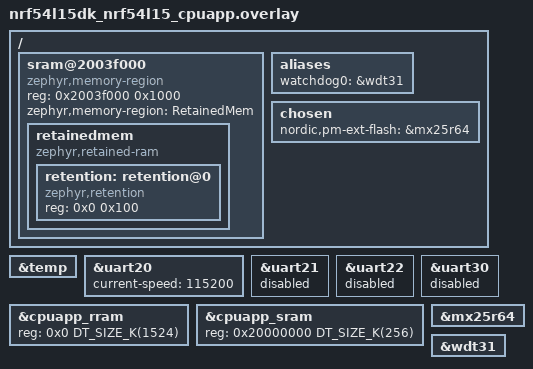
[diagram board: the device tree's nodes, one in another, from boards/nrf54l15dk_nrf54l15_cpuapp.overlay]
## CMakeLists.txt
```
cmake_minimum_required(VERSION 3.20.0)

find_package(Zephyr HINTS $ENV{ZEPHYR_BASE})

project(nrf54_soil)

# Enable GNU STD support for Matter to use
include(${ZEPHYR_CONNECTEDHOMEIP_MODULE_DIR}/config/nrfconnect/app/enable-gnu-std.cmake)

# Matter data model generation
include(${ZEPHYR_CONNECTEDHOMEIP_MODULE_DIR}/src/app/chip_data_model.cmake)

target_include_directories(app PRIVATE
    src
    src/zap-generated
)

target_sources(app PRIVATE
    src/main.cpp
    src/app_task.cpp
    src/retained.cpp
)

target_sources_ifdef(CONFIG_APP_BATTERY_MONITORING app PRIVATE
    src/battery.cpp
)

target_include_directories(matter-data-model PUBLIC
    src
)

chip_configure_data_model(app
    BYPASS_IDL
    GEN_DIR src/zap-generated
    ZAP_FILE ${CMAKE_CURRENT_SOURCE_DIR}/src/sensor.zap
)
```

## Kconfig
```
mainmenu "nRF54 Soil Moisture Sensor Configuration"

config APP_BATTERY_MONITORING
	bool "Enable battery voltage monitoring"
	default y
	select ADC
	help
	  Enable battery voltage monitoring via ADC and voltage divider.

config APP_TEMPERATURE_MONITORING
	bool "Enable temperature monitoring"
	default y
	select SENSOR
	help
	  Enable internal die temperature sensor monitoring.

config APP_MEASUREMENT_INTERVAL_SEC
	int "Measurement interval (seconds)"
	default 300
	help
	  Time between periodic measurements. Device sleeps between readings.


choice OPENTHREAD_DEVICE_TYPE
	default OPENTHREAD_MTD
endchoice

source "${ZEPHYR_CONNECTEDHOMEIP_MODULE_DIR}/config/nrfconnect/chip-module/Kconfig.features"
source "${ZEPHYR_CONNECTEDHOMEIP_MODULE_DIR}/config/nrfconnect/chip-module/Kconfig.defaults"
source "Kconfig.zephyr"
```

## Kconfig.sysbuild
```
# nRF54 Soil Moisture Sensor - Sysbuild Configuration

#### Bootloader
choice BOOTLOADER
	default BOOTLOADER_MCUBOOT
endchoice

if BOOTLOADER_MCUBOOT

config PM_OVERRIDE_EXTERNAL_DRIVER_CHECK
	default y

# MCUboot padding size
config PM_MCUBOOT_PAD
	default 0x800

# Use overwrite-only mode (simpler, no swap)
choice MCUBOOT_MODE
	default MCUBOOT_MODE_OVERWRITE_ONLY
endchoice

endif # BOOTLOADER_MCUBOOT

source "share/sysbuild/Kconfig"
```

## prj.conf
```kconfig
# nRF54 Soil Moisture Sensor - Debug Configuration
# Development build with full logging

# Application features
CONFIG_APP_TEMPERATURE_MONITORING=y
CONFIG_APP_MEASUREMENT_INTERVAL_SEC=5

# Enable CHIP
CONFIG_CHIP=y
CONFIG_CHIP_DEVICE_PRODUCT_ID=32781
CONFIG_CHIP_PROJECT_CONFIG="src/chip_project_config.h"
CONFIG_STD_CPP17=y
CONFIG_THREAD_NAME=y
CONFIG_MPU_STACK_GUARD=y
CONFIG_CHIP_LIB_SHELL=y
CONFIG_CHIP_ENABLE_PAIRING_AUTOSTART=y

# Enable Intermittently Connected Device support,
# with Long Idle Time to reduce power usage
CONFIG_CHIP_ENABLE_ICD_SUPPORT=y
CONFIG_CHIP_ICD_LIT_SUPPORT=y

# Enable Matter extended announcement and increase duration to 1 hour
CONFIG_CHIP_BLE_EXT_ADVERTISING=y
CONFIG_CHIP_BLE_ADVERTISING_DURATION=60

# OpenThread shell for debugging
CONFIG_OPENTHREAD_SHELL=y
CONFIG_SHELL_BACKEND_SERIAL_RX_RING_BUFFER_SIZE=256

# GRTC timer for wakeup from System OFF
CONFIG_NRF_GRTC_TIMER=y

# RAM retention in System OFF
CONFIG_RETAINED_MEM=y
CONFIG_RETAINED_MEM_MUTEX_FORCE_DISABLE=y
CONFIG_RETENTION=y
CONFIG_CRC=y

# Hardware info for reset cause detection
CONFIG_HWINFO=y

# Power Management
CONFIG_PM_DEVICE=y
CONFIG_PM_DEVICE_RUNTIME=y

# System Off (deep sleep)
CONFIG_POWEROFF=y

# Memory footprint
CONFIG_HEAP_MEM_POOL_SIZE=1024
CONFIG_IDLE_STACK_SIZE=256

# Minimal libc
CONFIG_MINIMAL_LIBC=y

# Console for debugging
CONFIG_CONSOLE=y
CONFIG_UART_CONSOLE=y

# Configure UART async logging and shell
CONFIG_LOG=y
CONFIG_LOG_MODE_DEFERRED=y
CONFIG_LOG_PROCESS_THREAD_STACK_SIZE=1024
CONFIG_LOG_BUFFER_SIZE=4096
CONFIG_LOG_FUNC_NAME_PREFIX_DBG=n
CONFIG_SHELL=y
CONFIG_SHELL_LOG_BACKEND=y

# Size optimizations
CONFIG_SIZE_OPTIMIZATIONS=y
CONFIG_LTO=y

# Matter/CHIP size optimizations
CONFIG_CHIP_LOG_SIZE_OPTIMIZATION=y
CONFIG_CHIP_TASK_STACK_SIZE=6144
CONFIG_CHIP_MALLOC_SYS_HEAP_SIZE=8192
CONFIG_CHIP_SYSTEM_PACKETBUFFER_POOL_SIZE=10
CONFIG_CHIP_OTA_REQUESTOR_BUFFER_SIZE=512

# Reduce BLE buffers
CONFIG_BT_BUF_EVT_RX_COUNT=8
CONFIG_BT_BUF_ACL_RX_COUNT=4
CONFIG_BT_BUF_CMD_TX_COUNT=4

# TODO Not sure why this is needed, without it we stack overflow main upon commisioning
CONFIG_MAIN_STACK_SIZE=8196
CONFIG_MATTER_LOG_LEVEL_DBG=y
```

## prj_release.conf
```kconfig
# nRF54 Soil Moisture Sensor - Release Configuration Overrides
# Optimized to reduce power consumption

# Application features
CONFIG_APP_MEASUREMENT_INTERVAL_SEC=300

# Disable all logging
CONFIG_LOG=n

# Disable Matter/CHIP logging (0 = OFF)
CONFIG_CHIP_APP_LOG_LEVEL=0

# Disable console/UART
CONFIG_CONSOLE=n
CONFIG_UART_CONSOLE=n
CONFIG_SERIAL=n

# Disable assertions
CONFIG_ASSERT=n
CONFIG_ASSERT_VERBOSE=n

# Disable debug features
CONFIG_DEBUG=n
CONFIG_DEBUG_INFO=n
CONFIG_THREAD_NAME=n
CONFIG_PRINTK=n
CONFIG_BOOT_BANNER=n

# Disable shell
CONFIG_SHELL=n
CONFIG_CHIP_LIB_SHELL=n
```

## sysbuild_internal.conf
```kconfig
SB_CONFIG_MATTER=y
SB_CONFIG_PM_OVERRIDE_EXTERNAL_DRIVER_CHECK=n
SB_CONFIG_PM_EXTERNAL_FLASH_MCUBOOT_SECONDARY=n

# Enable image compression
SB_CONFIG_MCUBOOT_MODE_OVERWRITE_ONLY=y
SB_CONFIG_MCUBOOT_COMPRESSED_IMAGE_SUPPORT=y
```

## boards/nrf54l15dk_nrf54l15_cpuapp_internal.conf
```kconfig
#
# Copyright (c) 2024 Nordic Semiconductor ASA
#
# SPDX-License-Identifier: LicenseRef-Nordic-5-Clause
#

# Disable SPI
CONFIG_CHIP_SPI_NOR=n

# Enable LTO to decrease the flash usage.
CONFIG_LTO=y
CONFIG_ISR_TABLES_LOCAL_DECLARATION=y
```

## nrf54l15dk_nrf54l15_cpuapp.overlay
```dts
/*
 * Device Tree Overlay for nRF54 Soil Sensor
 * Configures ADC for battery voltage monitoring
 */

#include <zephyr/dt-bindings/adc/nrf-saadc.h>

/ {
	/* Define voltage divider on battery input */
	vbatt {
		compatible = "voltage-divider";
		io-channels = <&adc 0>;
		output-ohms = <22000000>;  /* 22M lower resistor */
		full-ohms = <44000000>;    /* 22M + 22M = 44M total (1:2 divider) */
		/* High resistance (22M) minimizes current drain: 4.2V/44M = 95nA */
	};

	/* Retained RAM for state across System OFF */
	sram@2003f000 {
		compatible = "zephyr,memory-region", "mmio-sram";
		reg = <0x2003f000 0x1000>;
		zephyr,memory-region = "RetainedMem";
		status = "okay";

		retainedmem {
			compatible = "zephyr,retained-ram";
			status = "okay";
			#address-cells = <1>;
			#size-cells = <1>;

			retention: retention@0 {
				compatible = "zephyr,retention";
				status = "okay";
				reg = <0x0 0x100>;
			};
		};
	};

	/* Alias for easy access */
	aliases {
		battery-adc = &adc;
	};
};

/* Configure SAADC for battery voltage measurement */
&adc {
	status = "okay";
	#address-cells = <1>;
	#size-cells = <0>;

	channel@0 {
		reg = <0>;
		zephyr,gain = "ADC_GAIN_1_6";
		zephyr,reference = "ADC_REF_INTERNAL";
		zephyr,acquisition-time = <ADC_ACQ_TIME_DEFAULT>;
		zephyr,input-positive = <NRF_SAADC_AIN0>;  /* P0.00 */
		zephyr,resolution = <12>;
		zephyr,oversampling = <4>;  /* Average 4 samples for stability */
	};
};

/* Enable internal temperature sensor */
&temp {
	status = "okay";
};

/* Keep UART20 for console (it's the default console) */
&uart20 {
	status = "okay";
	current-speed = <115200>;
};

/* Disable unused peripherals to save power */
&uart21 {
	status = "disabled";
};

&uart22 {
	status = "disabled";
};

&uart30 {
	status = "disabled";
};
```

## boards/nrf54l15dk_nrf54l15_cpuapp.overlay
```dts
/ {
	/* Retained RAM for state across System OFF */
	sram@2003f000 {
		compatible = "zephyr,memory-region", "mmio-sram";
		reg = <0x2003f000 0x1000>;
		zephyr,memory-region = "RetainedMem";
		status = "okay";

		retainedmem {
			compatible = "zephyr,retained-ram";
			status = "okay";
			#address-cells = <1>;
			#size-cells = <1>;

			retention: retention@0 {
				compatible = "zephyr,retention";
				status = "okay";
				reg = <0x0 0x100>;
			};
		};
	};

	aliases {
		watchdog0 = &wdt31;
	};

	chosen {
		nordic,pm-ext-flash = &mx25r64;
	};
};

/* Enable internal temperature sensor */
&temp {
	status = "okay";
};

/* Keep UART20 for console (it's the default console) */
&uart20 {
	status = "okay";
	current-speed = <115200>;
};

/* Disable unused peripherals to save power */
&uart21 {
	status = "disabled";
};

&uart22 {
	status = "disabled";
};

&uart30 {
	status = "disabled";
};

// restore full RRAM and SRAM space - by default some parts are dedicated to FLRP
&cpuapp_rram {
	reg = <0x0 DT_SIZE_K(1524)>;
};

&cpuapp_sram {
	reg = <0x20000000 DT_SIZE_K(256)>;
	ranges = <0x0 0x20000000  0x40000>;
};

&mx25r64 {
	status = "okay";
};

&wdt31 {
	status = "okay";
};
```

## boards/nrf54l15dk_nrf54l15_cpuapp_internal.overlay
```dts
/ {
	/* Retained RAM for state across System OFF */
	sram@2003f000 {
		compatible = "zephyr,memory-region", "mmio-sram";
		reg = <0x2003f000 0x1000>;
		zephyr,memory-region = "RetainedMem";
		status = "okay";

		retainedmem {
			compatible = "zephyr,retained-ram";
			status = "okay";
			#address-cells = <1>;
			#size-cells = <1>;

			retention: retention@0 {
				compatible = "zephyr,retention";
				status = "okay";
				reg = <0x0 0x100>;
			};
		};
	};

	aliases {
		battery-adc = &adc;
		// Use watchdog wdt31 as the application watchdog
		watchdog0 = &wdt31;
	};
};

/* Enable internal temperature sensor */
&temp {
	status = "okay";
};

/* Keep UART20 for console (it's the default console) */
&uart20 {
	status = "okay";
	current-speed = <115200>;
};

/* Disable unused peripherals to save power */
&uart21 {
	status = "disabled";
};

&uart22 {
	status = "disabled";
};

&uart30 {
	status = "disabled";
};

// restore full RRAM and SRAM space - by default some parts are dedicated to FLRP
&cpuapp_rram {
	reg = <0x0 DT_SIZE_K(1524)>;
};

&cpuapp_sram {
	reg = <0x20000000 DT_SIZE_K(256)>;
	ranges = <0x0 0x20000000  0x40000>;
};

// Disable external flash
&mx25r64 {
	status = "disabled";
};

&wdt31 {
	status = "okay";
};
```

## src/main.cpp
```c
/*
 * nRF54 Soil Moisture Sensor - Main Entry Point
 */

#include "app_task.h"

#include <zephyr/logging/log.h>

LOG_MODULE_REGISTER(app, CONFIG_CHIP_APP_LOG_LEVEL);

int main()
{
	CHIP_ERROR err = AppTask::Instance().StartApp();

	LOG_ERR("Exited with code %" CHIP_ERROR_FORMAT, err.Format());
	return err == CHIP_NO_ERROR ? EXIT_SUCCESS : EXIT_FAILURE;
}
```

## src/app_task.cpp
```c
/*
 * nRF54 Soil Moisture Sensor - Matter Application Task
 */

#include "app_task.h"

#include "lib/core/CHIPError.h"
#include "lib/support/CodeUtils.h"

#include <zephyr/kernel.h>
#include <zephyr/logging/log.h>

LOG_MODULE_REGISTER(app_task, CONFIG_CHIP_APP_LOG_LEVEL);

using namespace ::chip;

CHIP_ERROR AppTask::Init()
{
	LOG_INF("AppTask::Init");
	return CHIP_NO_ERROR;
}

CHIP_ERROR AppTask::StartApp()
{
	ReturnErrorOnFailure(Init());

	LOG_INF("Matter application started");

	while (true) {
		k_sleep(K_FOREVER);
	}

	return CHIP_NO_ERROR;
}
```

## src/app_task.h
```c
/*
 * nRF54 Soil Moisture Sensor - Matter Application Task
 */

#pragma once

#include <lib/core/CHIPError.h>

class AppTask {
public:
	static AppTask &Instance()
	{
		static AppTask sAppTask;
		return sAppTask;
	}

	CHIP_ERROR StartApp();

private:
	CHIP_ERROR Init();
};
```

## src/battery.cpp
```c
/*
 * Battery Monitoring Implementation
 */

#include "battery.h"
#include <zephyr/drivers/adc.h>
#include <zephyr/logging/log.h>

LOG_MODULE_REGISTER(battery, LOG_LEVEL_INF);

/* Device tree node for voltage divider */
#define VBATT DT_PATH(vbatt)

/* Get ADC spec and voltage divider properties from device tree */
static const struct adc_dt_spec adc_spec = ADC_DT_SPEC_GET(VBATT);
static const uint32_t full_ohms = DT_PROP(VBATT, full_ohms);
static const uint32_t output_ohms = DT_PROP(VBATT, output_ohms);

static int16_t adc_sample_buffer;
static struct adc_sequence sequence = {
	.buffer = &adc_sample_buffer,
	.buffer_size = sizeof(adc_sample_buffer),
	.calibrate = true,  /* Enable ADC calibration for accuracy */
};

static int32_t last_voltage_mv = 0;

int battery_init(void)
{
	int ret;

	if (!adc_is_ready_dt(&adc_spec)) {
		LOG_ERR("ADC device not ready");
		return -ENODEV;
	}

	ret = adc_channel_setup_dt(&adc_spec);
	if (ret < 0) {
		LOG_ERR("Failed to setup ADC channel: %d", ret);
		return ret;
	}

	/* Initialize ADC sequence from device tree */
	ret = adc_sequence_init_dt(&adc_spec, &sequence);
	if (ret < 0) {
		LOG_ERR("Failed to initialize ADC sequence: %d", ret);
		return ret;
	}

	LOG_INF("Battery monitoring initialized");
	LOG_INF("  ADC resolution: %d bits", sequence.resolution);
	LOG_INF("  Voltage divider: %u ohm / %u ohm", full_ohms, output_ohms);

	/* Perform initial reading */
	ret = battery_read_voltage(&last_voltage_mv);
	if (ret == 0) {
		LOG_INF("  Initial voltage: %d mV", last_voltage_mv);
	}

	return 0;
}

int battery_read_voltage(int32_t *voltage_mv)
{
	int ret;
	int32_t adc_value_mv;

	if (!voltage_mv) {
		return -EINVAL;
	}

	/* Read ADC */
	ret = adc_read_dt(&adc_spec, &sequence);
	if (ret < 0) {
		LOG_ERR("ADC read failed: %d", ret);
		return ret;
	}

	/* Convert raw ADC value to millivolts at ADC pin
	 * This accounts for gain and reference voltage automatically */
	adc_value_mv = (int32_t)adc_sample_buffer;
	ret = adc_raw_to_millivolts_dt(&adc_spec, &adc_value_mv);
	if (ret < 0) {
		LOG_ERR("ADC conversion failed: %d", ret);
		return ret;
	}

	/* Apply voltage divider ratio to get actual battery voltage
	 * Use 64-bit intermediate to prevent overflow */
	*voltage_mv = (int32_t)((int64_t)adc_value_mv * full_ohms / output_ohms);

	last_voltage_mv = *voltage_mv;

	LOG_DBG("ADC sample: %d, ADC voltage: %d mV, Battery voltage: %d mV",
		adc_sample_buffer, adc_value_mv, *voltage_mv);

	return 0;
}

enum battery_state battery_get_state(void)
{
	if (last_voltage_mv == 0) {
		/* No reading yet */
		return BATTERY_STATE_UNKNOWN;
	}

	if (last_voltage_mv < BATTERY_VOLTAGE_CRITICAL) {
		return BATTERY_STATE_CRITICAL;
	} else if (last_voltage_mv < BATTERY_VOLTAGE_LOW) {
		return BATTERY_STATE_LOW;
	} else if (last_voltage_mv < BATTERY_VOLTAGE_GOOD) {
		return BATTERY_STATE_GOOD;
	} else {
		return BATTERY_STATE_FULL;
	}
}

uint8_t battery_get_percentage(void)
{
	int32_t voltage = last_voltage_mv;

	/* Simple linear approximation for Li-ion battery:
	 * 4.2V = 100%
	 * 3.7V = 50%
	 * 3.0V = 5%
	 * 2.7V = 0%
	 */

	if (voltage >= BATTERY_VOLTAGE_FULL) {
		return 100;
	} else if (voltage <= BATTERY_VOLTAGE_CRITICAL) {
		return 0;
	}

	/* Linear interpolation between critical and full */
	int32_t range = BATTERY_VOLTAGE_FULL - BATTERY_VOLTAGE_CRITICAL;
	int32_t offset = voltage - BATTERY_VOLTAGE_CRITICAL;

	return (uint8_t)((offset * 100) / range);
}

bool battery_is_critical(void)
{
	return (battery_get_state() == BATTERY_STATE_CRITICAL);
}
```

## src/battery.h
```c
/*
 * Battery Monitoring Module
 * ADC-based voltage measurement with low battery detection
 */

#ifndef BATTERY_H
#define BATTERY_H

#include <zephyr/kernel.h>
#include <stdint.h>

/* Battery voltage thresholds (in millivolts) */
#define BATTERY_VOLTAGE_CRITICAL    2700    /* Enter deep sleep immediately */
#define BATTERY_VOLTAGE_LOW         3000    /* Warning threshold */
#define BATTERY_VOLTAGE_GOOD        3300    /* Normal operation */
#define BATTERY_VOLTAGE_FULL        4200    /* Fully charged (Li-ion) */

/* Battery state */
enum battery_state {
	BATTERY_STATE_CRITICAL,    /* < 2.7V - shut down */
	BATTERY_STATE_LOW,         /* 2.7V - 3.0V - conserve power */
	BATTERY_STATE_GOOD,        /* 3.0V - 3.3V - normal operation */
	BATTERY_STATE_FULL,        /* > 3.3V - fully charged */
	BATTERY_STATE_UNKNOWN,     /* Not yet measured */
};

/**
 * Initialize battery monitoring subsystem
 * @return 0 on success, negative errno on failure
 */
int battery_init(void);

/**
 * Read current battery voltage in millivolts
 * @param voltage_mv Pointer to store voltage reading
 * @return 0 on success, negative errno on failure
 */
int battery_read_voltage(int32_t *voltage_mv);

/**
 * Get current battery state based on voltage
 * @return Battery state enum
 */
enum battery_state battery_get_state(void);

/**
 * Get battery percentage (0-100%)
 * Based on voltage curve for Li-ion battery
 * @return Battery percentage
 */
uint8_t battery_get_percentage(void);

/**
 * Check if battery is critically low and needs shutdown
 * @return true if critical, false otherwise
 */
bool battery_is_critical(void);

#endif /* BATTERY_H */
```

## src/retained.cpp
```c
/*
 * Retained RAM implementation
 */

#include "retained.h"
#include <zephyr/retention/retention.h>
#include <zephyr/sys/crc.h>

/* Retained data stored in special RAM section */
static const struct device *retention_dev = DEVICE_DT_GET(DT_NODELABEL(retention));

struct retained_data retained;

static uint32_t retained_checksum(void)
{
	return crc32_ieee((uint8_t *)&retained,
	                  offsetof(struct retained_data, checksum));
}

bool retained_validate(void)
{
	int ret;

	if (!device_is_ready(retention_dev)) {
		return false;
	}

	ret = retention_read(retention_dev, 0, (uint8_t *)&retained, sizeof(retained));
	if (ret < 0) {
		return false;
	}

	if (retained.magic != RETAINED_MAGIC) {
		return false;
	}

	return retained.checksum == retained_checksum();
}

void retained_update(void)
{
	retained.magic = RETAINED_MAGIC;
	retained.checksum = retained_checksum();

	if (device_is_ready(retention_dev)) {
		retention_write(retention_dev, 0, (uint8_t *)&retained, sizeof(retained));
	}
}
```

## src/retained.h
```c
/*
 * Retained RAM structure for nRF54 Soil Moisture Sensor
 * Preserves state across System OFF sleep cycles
 */

#ifndef RETAINED_H
#define RETAINED_H

#include <zephyr/kernel.h>
#include <zephyr/retention/retention.h>

/* Retained state structure */
struct retained_data {
	uint32_t magic;           /* Magic number for validation */
	uint32_t measurement_count; /* Number of measurements taken */
	uint32_t boot_count;      /* Number of cold boots */
	int16_t last_temp_c;      /* Last temperature (°C * 100) */
	int32_t last_voltage_mv;  /* Last battery voltage (mV) */
	uint32_t checksum;        /* Simple checksum */
};

/* Magic number to validate retained data */
#define RETAINED_MAGIC 0x534F494C  /* "SOIL" in ASCII */

/* Global retained data instance */
extern struct retained_data retained;

/**
 * Validate retained data
 * @return true if valid, false if corrupted
 */
bool retained_validate(void);

/**
 * Update checksum in retained data
 */
void retained_update(void);

#endif /* RETAINED_H */
```
